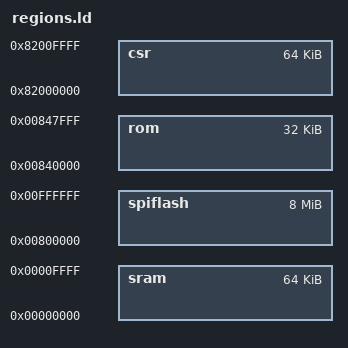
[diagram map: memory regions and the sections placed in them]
MEMORY {
	sram : ORIGIN = 0x00000000, LENGTH = 0x00010000
	spiflash : ORIGIN = 0x00800000, LENGTH = 0x00800000
	rom : ORIGIN = 0x00840000, LENGTH = 0x00008000
	csr : ORIGIN = 0x82000000, LENGTH = 0x00010000
}
